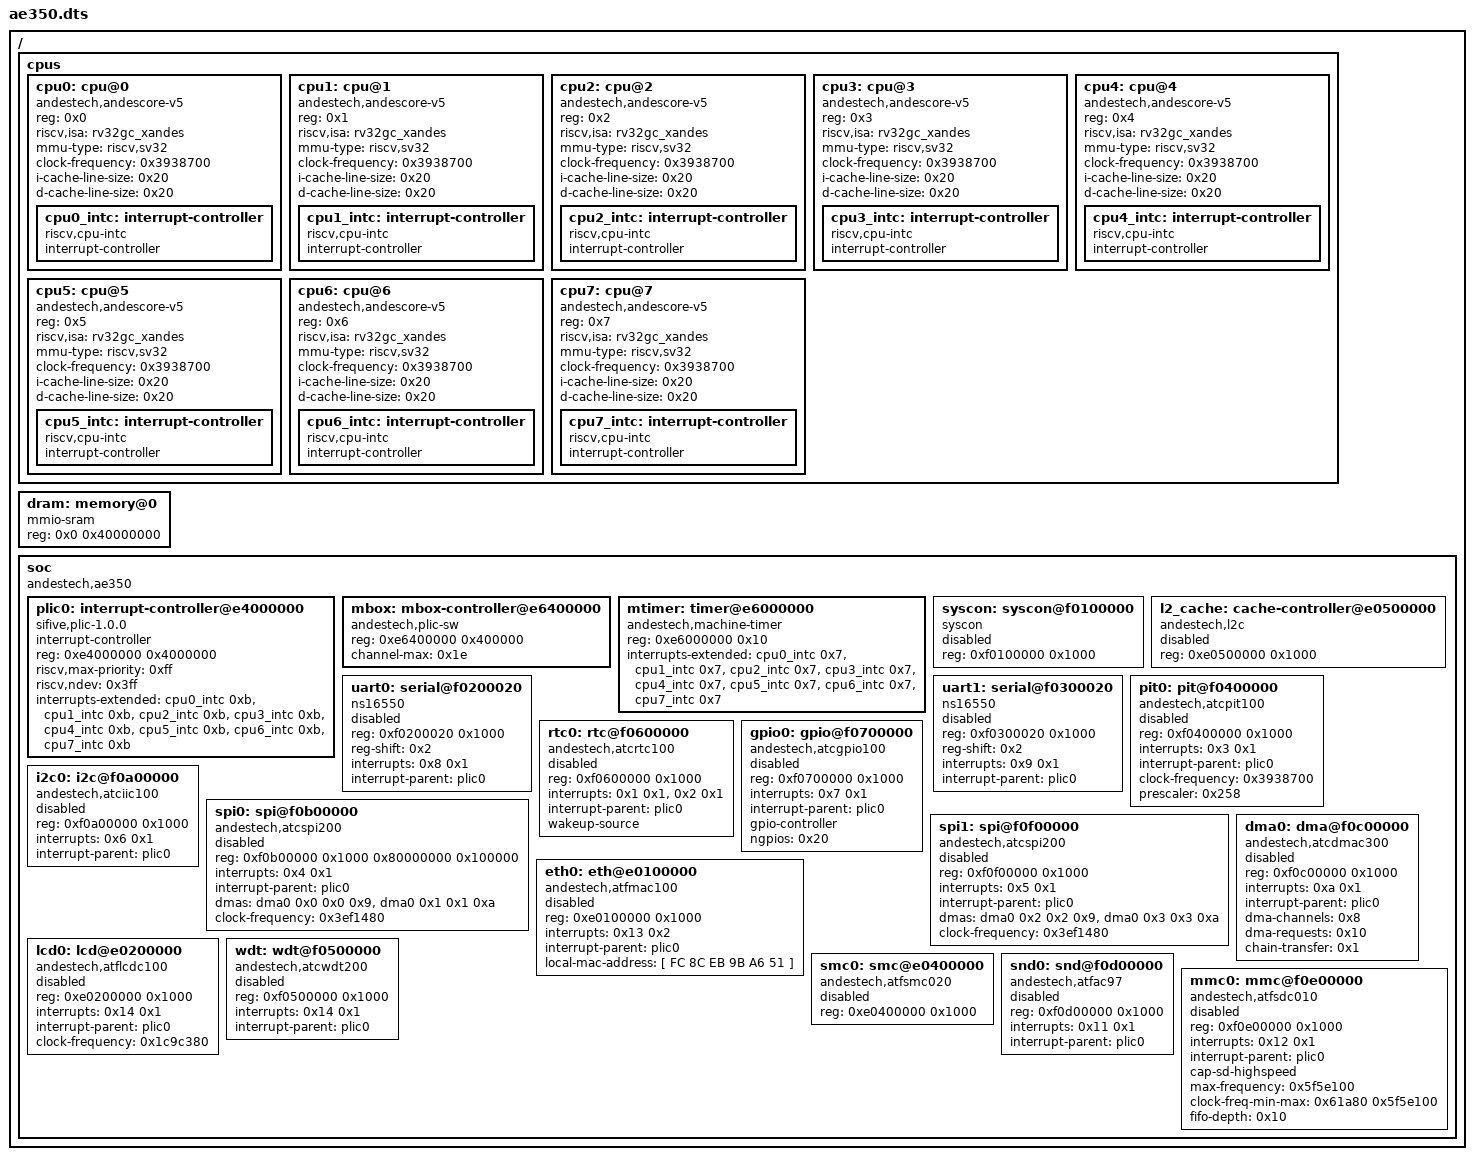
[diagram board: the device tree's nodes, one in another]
/dts-v1/;

/ {
	#address-cells = < 0x1 >;
	#size-cells = < 0x1 >;
	cpus {
		#address-cells = < 0x1 >;
		#size-cells = < 0x0 >;
		cpu0: cpu@0 {
			compatible = "andestech,andescore-v5", "riscv";
			device_type = "cpu";
			reg = < 0x0 >;
			status = "okay";
			riscv,isa = "rv32gc_xandes";
			mmu-type = "riscv,sv32";
			clock-frequency = < 0x3938700 >;
			i-cache-line-size = < 0x20 >;
			d-cache-line-size = < 0x20 >;
			cpu0_intc: interrupt-controller {
				compatible = "riscv,cpu-intc";
				#address-cells = < 0x0 >;
				#interrupt-cells = < 0x1 >;
				interrupt-controller;
				phandle = < 0x1 >;
			};
		};
		cpu1: cpu@1 {
			compatible = "andestech,andescore-v5", "riscv";
			device_type = "cpu";
			reg = < 0x1 >;
			status = "okay";
			riscv,isa = "rv32gc_xandes";
			mmu-type = "riscv,sv32";
			clock-frequency = < 0x3938700 >;
			i-cache-line-size = < 0x20 >;
			d-cache-line-size = < 0x20 >;
			cpu1_intc: interrupt-controller {
				compatible = "riscv,cpu-intc";
				#address-cells = < 0x0 >;
				#interrupt-cells = < 0x1 >;
				interrupt-controller;
				phandle = < 0x2 >;
			};
		};
		cpu2: cpu@2 {
			compatible = "andestech,andescore-v5", "riscv";
			device_type = "cpu";
			reg = < 0x2 >;
			status = "okay";
			riscv,isa = "rv32gc_xandes";
			mmu-type = "riscv,sv32";
			clock-frequency = < 0x3938700 >;
			i-cache-line-size = < 0x20 >;
			d-cache-line-size = < 0x20 >;
			cpu2_intc: interrupt-controller {
				compatible = "riscv,cpu-intc";
				#address-cells = < 0x0 >;
				#interrupt-cells = < 0x1 >;
				interrupt-controller;
				phandle = < 0x3 >;
			};
		};
		cpu3: cpu@3 {
			compatible = "andestech,andescore-v5", "riscv";
			device_type = "cpu";
			reg = < 0x3 >;
			status = "okay";
			riscv,isa = "rv32gc_xandes";
			mmu-type = "riscv,sv32";
			clock-frequency = < 0x3938700 >;
			i-cache-line-size = < 0x20 >;
			d-cache-line-size = < 0x20 >;
			cpu3_intc: interrupt-controller {
				compatible = "riscv,cpu-intc";
				#address-cells = < 0x0 >;
				#interrupt-cells = < 0x1 >;
				interrupt-controller;
				phandle = < 0x4 >;
			};
		};
		cpu4: cpu@4 {
			compatible = "andestech,andescore-v5", "riscv";
			device_type = "cpu";
			reg = < 0x4 >;
			status = "okay";
			riscv,isa = "rv32gc_xandes";
			mmu-type = "riscv,sv32";
			clock-frequency = < 0x3938700 >;
			i-cache-line-size = < 0x20 >;
			d-cache-line-size = < 0x20 >;
			cpu4_intc: interrupt-controller {
				compatible = "riscv,cpu-intc";
				#address-cells = < 0x0 >;
				#interrupt-cells = < 0x1 >;
				interrupt-controller;
				phandle = < 0x5 >;
			};
		};
		cpu5: cpu@5 {
			compatible = "andestech,andescore-v5", "riscv";
			device_type = "cpu";
			reg = < 0x5 >;
			status = "okay";
			riscv,isa = "rv32gc_xandes";
			mmu-type = "riscv,sv32";
			clock-frequency = < 0x3938700 >;
			i-cache-line-size = < 0x20 >;
			d-cache-line-size = < 0x20 >;
			cpu5_intc: interrupt-controller {
				compatible = "riscv,cpu-intc";
				#address-cells = < 0x0 >;
				#interrupt-cells = < 0x1 >;
				interrupt-controller;
				phandle = < 0x6 >;
			};
		};
		cpu6: cpu@6 {
			compatible = "andestech,andescore-v5", "riscv";
			device_type = "cpu";
			reg = < 0x6 >;
			status = "okay";
			riscv,isa = "rv32gc_xandes";
			mmu-type = "riscv,sv32";
			clock-frequency = < 0x3938700 >;
			i-cache-line-size = < 0x20 >;
			d-cache-line-size = < 0x20 >;
			cpu6_intc: interrupt-controller {
				compatible = "riscv,cpu-intc";
				#address-cells = < 0x0 >;
				#interrupt-cells = < 0x1 >;
				interrupt-controller;
				phandle = < 0x7 >;
			};
		};
		cpu7: cpu@7 {
			compatible = "andestech,andescore-v5", "riscv";
			device_type = "cpu";
			reg = < 0x7 >;
			status = "okay";
			riscv,isa = "rv32gc_xandes";
			mmu-type = "riscv,sv32";
			clock-frequency = < 0x3938700 >;
			i-cache-line-size = < 0x20 >;
			d-cache-line-size = < 0x20 >;
			cpu7_intc: interrupt-controller {
				compatible = "riscv,cpu-intc";
				#address-cells = < 0x0 >;
				#interrupt-cells = < 0x1 >;
				interrupt-controller;
				phandle = < 0x8 >;
			};
		};
	};
	dram: memory@0 {
		device_type = "memory";
		compatible = "mmio-sram";
		reg = < 0x0 0x40000000 >;
	};
	soc {
		#address-cells = < 0x1 >;
		#size-cells = < 0x1 >;
		compatible = "andestech,ae350";
		ranges;
		plic0: interrupt-controller@e4000000 {
			compatible = "sifive,plic-1.0.0", "andestech,nceplic100";
			#address-cells = < 0x1 >;
			#interrupt-cells = < 0x2 >;
			interrupt-controller;
			reg = < 0xe4000000 0x4000000 >;
			riscv,max-priority = < 0xff >;
			riscv,ndev = < 0x3ff >;
			interrupts-extended = < &cpu0_intc 0xb &cpu1_intc 0xb &cpu2_intc 0xb &cpu3_intc 0xb &cpu4_intc 0xb &cpu5_intc 0xb &cpu6_intc 0xb &cpu7_intc 0xb >;
			phandle = < 0x9 >;
		};
		mbox: mbox-controller@e6400000 {
			compatible = "andestech,plic-sw";
			reg = < 0xe6400000 0x400000 >;
			#mbox-cells = < 0x1 >;
			channel-max = < 0x1e >;
			status = "okay";
		};
		mtimer: timer@e6000000 {
			compatible = "andestech,machine-timer";
			reg = < 0xe6000000 0x10 >;
			interrupts-extended = < &cpu0_intc 0x7 &cpu1_intc 0x7 &cpu2_intc 0x7 &cpu3_intc 0x7 &cpu4_intc 0x7 &cpu5_intc 0x7 &cpu6_intc 0x7 &cpu7_intc 0x7 >;
		};
		syscon: syscon@f0100000 {
			compatible = "syscon", "andestech,atcsmu100";
			reg = < 0xf0100000 0x1000 >;
			status = "disabled";
		};
		l2_cache: cache-controller@e0500000 {
			compatible = "andestech,l2c";
			reg = < 0xe0500000 0x1000 >;
			status = "disabled";
		};
		uart0: serial@f0200020 {
			compatible = "ns16550";
			reg = < 0xf0200020 0x1000 >;
			reg-shift = < 0x2 >;
			interrupts = < 0x8 0x1 >;
			interrupt-parent = < &plic0 >;
			status = "disabled";
		};
		uart1: serial@f0300020 {
			compatible = "ns16550";
			reg = < 0xf0300020 0x1000 >;
			reg-shift = < 0x2 >;
			interrupts = < 0x9 0x1 >;
			interrupt-parent = < &plic0 >;
			status = "disabled";
		};
		pit0: pit@f0400000 {
			compatible = "andestech,atcpit100";
			reg = < 0xf0400000 0x1000 >;
			interrupts = < 0x3 0x1 >;
			interrupt-parent = < &plic0 >;
			clock-frequency = < 0x3938700 >;
			prescaler = < 0x258 >;
			status = "disabled";
		};
		rtc0: rtc@f0600000 {
			compatible = "andestech,atcrtc100";
			reg = < 0xf0600000 0x1000 >;
			interrupts = < 0x1 0x1 >, < 0x2 0x1 >;
			interrupt-parent = < &plic0 >;
			wakeup-source;
			status = "disabled";
		};
		gpio0: gpio@f0700000 {
			compatible = "andestech,atcgpio100";
			reg = < 0xf0700000 0x1000 >;
			interrupts = < 0x7 0x1 >;
			interrupt-parent = < &plic0 >;
			gpio-controller;
			ngpios = < 0x20 >;
			#gpio-cells = < 0x2 >;
			status = "disabled";
		};
		i2c0: i2c@f0a00000 {
			compatible = "andestech,atciic100";
			reg = < 0xf0a00000 0x1000 >;
			interrupts = < 0x6 0x1 >;
			interrupt-parent = < &plic0 >;
			#address-cells = < 0x1 >;
			#size-cells = < 0x0 >;
			status = "disabled";
		};
		spi0: spi@f0b00000 {
			compatible = "andestech,atcspi200";
			reg = < 0xf0b00000 0x1000 0x80000000 0x100000 >;
			reg-names = "control", "mem";
			interrupts = < 0x4 0x1 >;
			interrupt-parent = < &plic0 >;
			dmas = < &dma0 0x0 0x0 0x9 >, < &dma0 0x1 0x1 0xa >;
			dma-names = "tx", "rx";
			#address-cells = < 0x1 >;
			#size-cells = < 0x0 >;
			clock-frequency = < 0x3ef1480 >;
			status = "disabled";
		};
		spi1: spi@f0f00000 {
			compatible = "andestech,atcspi200";
			reg = < 0xf0f00000 0x1000 >;
			reg-names = "control";
			interrupts = < 0x5 0x1 >;
			interrupt-parent = < &plic0 >;
			dmas = < &dma0 0x2 0x2 0x9 >, < &dma0 0x3 0x3 0xa >;
			dma-names = "tx", "rx";
			#address-cells = < 0x1 >;
			#size-cells = < 0x0 >;
			clock-frequency = < 0x3ef1480 >;
			status = "disabled";
		};
		dma0: dma@f0c00000 {
			compatible = "andestech,atcdmac300";
			reg = < 0xf0c00000 0x1000 >;
			interrupts = < 0xa 0x1 >;
			interrupt-parent = < &plic0 >;
			dma-channels = < 0x8 >;
			dma-requests = < 0x10 >;
			chain-transfer = < 0x1 >;
			#dma-cells = < 0x3 >;
			status = "disabled";
			phandle = < 0xa >;
		};
		eth0: eth@e0100000 {
			compatible = "andestech,atfmac100";
			reg = < 0xe0100000 0x1000 >;
			interrupts = < 0x13 0x2 >;
			interrupt-parent = < &plic0 >;
			local-mac-address = [ FC 8C EB 9B A6 51 ];
			status = "disabled";
		};
		lcd0: lcd@e0200000 {
			compatible = "andestech,atflcdc100";
			reg = < 0xe0200000 0x1000 >;
			interrupts = < 0x14 0x1 >;
			interrupt-parent = < &plic0 >;
			clock-frequency = < 0x1c9c380 >;
			status = "disabled";
		};
		wdt: wdt@f0500000 {
			compatible = "andestech,atcwdt200";
			reg = < 0xf0500000 0x1000 >;
			interrupts = < 0x14 0x1 >;
			interrupt-parent = < &plic0 >;
			status = "disabled";
		};
		smc0: smc@e0400000 {
			compatible = "andestech,atfsmc020";
			reg = < 0xe0400000 0x1000 >;
			status = "disabled";
		};
		snd0: snd@f0d00000 {
			compatible = "andestech,atfac97";
			reg = < 0xf0d00000 0x1000 >;
			interrupts = < 0x11 0x1 >;
			interrupt-parent = < &plic0 >;
			status = "disabled";
		};
		mmc0: mmc@f0e00000 {
			compatible = "andestech,atfsdc010";
			reg = < 0xf0e00000 0x1000 >;
			interrupts = < 0x12 0x1 >;
			interrupt-parent = < &plic0 >;
			cap-sd-highspeed;
			max-frequency = < 0x5f5e100 >;
			clock-freq-min-max = < 0x61a80 0x5f5e100 >;
			fifo-depth = < 0x10 >;
			status = "disabled";
		};
	};
};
